VERSION ""

NS_ :

BS_:

BU_: Gateway IEB
VAL_TABLE_ vtbSensorReqCause 15 "SNA" 2 "by Request 2" 1 "by Request 1" 0 "normal cycle" ;
VAL_TABLE_ vtbErrorDescription 255 "ERROR" ;

BO_ 513 m_IEB_DiagRes: 1 IEB
 SG_ s_IEB_Brake_DiagRes : 0|1@1+ (1,0) [0|1] ""  Gateway

BO_ 512 m_IEB_DiagReq: 1 Gateway
 SG_ s_IEB_DiagReq : 0|1@1+ (1,0) [0|1] ""  IEB

BO_ 257 m_UserRegenStep: 1 Gateway
 SG_ s_UserRegenStep : 0|2@1+ (1,0) [0|3] ""  IEB

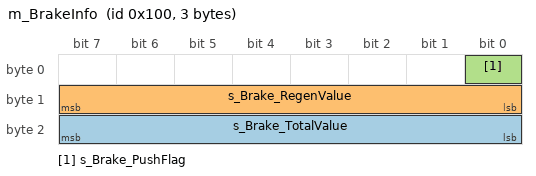
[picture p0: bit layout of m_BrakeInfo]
BO_ 256 m_BrakeInfo: 3 IEB
 SG_ s_Brake_TotalValue : 16|8@1+ (1,0) [0|255] ""  Gateway
 SG_ s_Brake_RegenValue : 8|8@1+ (1,0) [0|255] ""  Gateway
 SG_ s_Brake_PushFlag : 0|1@1+ (1,0) [0|1] ""  Gateway

BA_DEF_  "Manufacturer" STRING ;
BA_DEF_ BU_  "NodeLayerModules" STRING ;
BA_DEF_  "BusType" STRING ;
BA_DEF_ SG_  "GenSigSendType" ENUM  "Cyclic","OnWrite","OnWriteWithRepetition","OnChange","OnChangeWithRepetition","IfActive","IfActiveWithRepetition","NoSigSendType","NotUsed","NotUsed","NotUsed","NotUsed","NotUsed";
BA_DEF_ BO_  "GenMsgSendType" ENUM  "Cyclic","NotUsed","NotUsed","NotUsed","NotUsed","Cyclic","NotUsed","IfActive","NoMsgSendType","NotUsed","vector_leerstring";
BA_DEF_ BO_  "GenMsgCycleTime" INT 0 50000;
BA_DEF_ BO_  "GenMsgCycleTimeFast" INT 0 50000;
BA_DEF_ BO_  "GenMsgILSupport" ENUM  "No","Yes";
BA_DEF_DEF_  "Manufacturer" "Vector";
BA_DEF_DEF_  "NodeLayerModules" "CANoeILNLVector.dll";
BA_DEF_DEF_  "BusType" "CAN";
BA_DEF_DEF_  "GenSigSendType" "Cyclic";
BA_DEF_DEF_  "GenMsgSendType" "NoMsgSendType";
BA_DEF_DEF_  "GenMsgCycleTime" 200;
BA_DEF_DEF_  "GenMsgCycleTimeFast" 20;
BA_DEF_DEF_  "GenMsgILSupport" "Yes";
BA_ "GenMsgSendType" BO_ 513 7;
BA_ "GenMsgSendType" BO_ 512 7;
BA_ "GenMsgSendType" BO_ 257 7;
BA_ "GenMsgCycleTime" BO_ 256 10;
BA_ "GenMsgSendType" BO_ 256 0;
